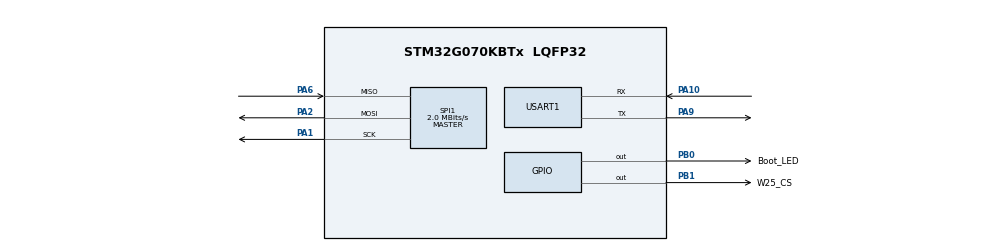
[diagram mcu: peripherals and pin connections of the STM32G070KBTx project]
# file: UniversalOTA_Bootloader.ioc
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Mcu.Family=STM32G0
Mcu.Name=STM32G070KBTx
Mcu.Package=LQFP32
NVIC.USART1_IRQn=true\:0\:0\:false\:false\:true\:true\:true\:true
PA1.Mode=Full_Duplex_Master
PA1.Signal=SPI1_SCK
PA10.Mode=Asynchronous
PA10.Signal=USART1_RX
PA13.Mode=Serial_Wire
PA13.Signal=SYS_SWDIO
PA14-BOOT0.Mode=Serial_Wire
PA14-BOOT0.Signal=SYS_SWCLK
PA2.Mode=Full_Duplex_Master
PA2.Signal=SPI1_MOSI
PA6.Mode=Full_Duplex_Master
PA6.Signal=SPI1_MISO
PA9.Mode=Asynchronous
PA9.Signal=USART1_TX
PB0.GPIO_Label=Boot_LED
PB0.Signal=GPIO_Output
PB1.GPIO_Label=W25_CS
PB1.Signal=GPIO_Output
ProjectManager.HeapSize=0x200
ProjectManager.StackSize=0x400
ProjectManager.TargetToolchain=STM32CubeIDE
SPI1.CalculateBaudRate=2.0 MBits/s
SPI1.DataSize=SPI_DATASIZE_8BIT
SPI1.Direction=SPI_DIRECTION_2LINES
SPI1.Mode=SPI_MODE_MASTER
SPI1.VirtualType=VM_MASTER
USART1.VirtualMode-Asynchronous=VM_ASYNC
VP_SYS_VS_DBSignals.Mode=DisableDeadBatterySignals
board=custom

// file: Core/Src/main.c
/* USER CODE BEGIN Header */
/**
  ******************************************************************************
  * @file           : main.c
  * @brief          : Main program body
  ******************************************************************************
  * @attention
  *
  * Copyright (c) 2026 STMicroelectronics.
  * All rights reserved.
  *
  * This software is licensed under terms that can be found in the LICENSE file
  * in the root directory of this software component.
  * If no LICENSE file comes with this software, it is provided AS-IS.
  *
  ******************************************************************************
  */
/* USER CODE END Header */
#include "main.h"
#include "spi.h"
#include "usart.h"
#include "gpio.h"
#include "hmac_test.h"

/* USER CODE BEGIN Includes */
#include "boot_manager.h"
/* USER CODE END Includes */

void SystemClock_Config(void);

int main(void)
{

  /* MCU Configuration--------------------------------------------------------*/

  /* Reset of all peripherals, Initializes the Flash interface and the Systick. */
  HAL_Init();

  /* Configure the system clock */
  SystemClock_Config();

  /* Initialize all configured peripherals */
  MX_GPIO_Init();
  MX_SPI1_Init();
  MX_USART1_UART_Init();
  /* USER CODE BEGIN 2 */
  HMACTest_Run();
  /* USER CODE END 2 */

  /* Infinite loop */
  while (1)
  {

  }
}

void SystemClock_Config(void)
{
  RCC_OscInitTypeDef RCC_OscInitStruct = {0};
  RCC_ClkInitTypeDef RCC_ClkInitStruct = {0};

  /** Configure the main internal regulator output voltage
  */
  HAL_PWREx_ControlVoltageScaling(PWR_REGULATOR_VOLTAGE_SCALE1);

  /** Initializes the RCC Oscillators according to the specified parameters
  * in the RCC_OscInitTypeDef structure.
  */
  RCC_OscInitStruct.OscillatorType = RCC_OSCILLATORTYPE_HSI;
  RCC_OscInitStruct.HSIState = RCC_HSI_ON;
  RCC_OscInitStruct.HSIDiv = RCC_HSI_DIV1;
  RCC_OscInitStruct.HSICalibrationValue = RCC_HSICALIBRATION_DEFAULT;
  RCC_OscInitStruct.PLL.PLLState = RCC_PLL_NONE;
  if (HAL_RCC_OscConfig(&RCC_OscInitStruct) != HAL_OK)
  {
    Error_Handler();
  }

  /** Initializes the CPU, AHB and APB buses clocks
  */
  RCC_ClkInitStruct.ClockType = RCC_CLOCKTYPE_HCLK|RCC_CLOCKTYPE_SYSCLK
                              |RCC_CLOCKTYPE_PCLK1;
  RCC_ClkInitStruct.SYSCLKSource = RCC_SYSCLKSOURCE_HSI;
  RCC_ClkInitStruct.AHBCLKDivider = RCC_SYSCLK_DIV1;
  RCC_ClkInitStruct.APB1CLKDivider = RCC_HCLK_DIV1;

  if (HAL_RCC_ClockConfig(&RCC_ClkInitStruct, FLASH_LATENCY_0) != HAL_OK)
  {
    Error_Handler();
  }
}

void Error_Handler(void)
{
  __disable_irq();
  while (1)
  {
  }
}
